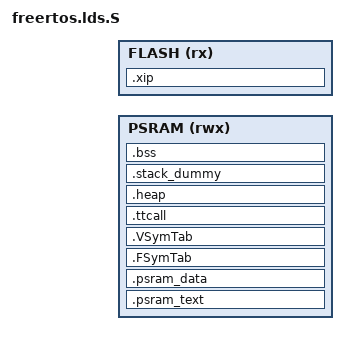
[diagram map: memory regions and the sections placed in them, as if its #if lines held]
/*******************************************************************/
/*                                                                 */
/* This file is automatically generated by linker script generator.*/
/*                                                                 */
/* Version:                                 */
/*                                                                 */
/* Copyright (c) 2010 Xilinx, Inc.  All rights reserved.           */
/*                                                                 */
/* Description : Cortex-A9 Linker Script                          */
/*                                                                 */
/*******************************************************************/
OUTPUT_ARCH("riscv")
OUTPUT_FORMAT("elf64-littleriscv","elf64-littleriscv","elf64-littleriscv")

#if (defined(CONFIG_ROM))
#include "rom_symbol.ld"
#endif

/* Linker script to configure memory regions. */
MEMORY
{
#if (defined(CONFIG_KASAN))
    PSRAM (rwx)   : ORIGIN = CONFIG_ARCH_START_ADDRESS, LENGTH = CONFIG_ARCH_MEM_LENGTH - (CONFIG_ARCH_MEM_LENGTH>>3)
#else
    PSRAM (rwx) : ORIGIN = CONFIG_ARCH_START_ADDRESS, LENGTH = CONFIG_ARCH_MEM_LENGTH
#endif
#if defined(CONFIG_XIP)
#if defined(CONFIG_DRIVERS_SPI_NOR_NG)
	FLASH (rx)  : ORIGIN = CONFIG_XIP_MEM_START_ADDR, LENGTH = CONFIG_XIP_MEM_LEN
#else
	FLASH (rx)  : ORIGIN = 0x10000000, LENGTH = 16M
#endif
#endif
}

__PSRAM_BASE = ORIGIN(PSRAM);
__PSRAM_LENGTH = LENGTH(PSRAM);
__MSP_STACK_LENGTH = 0x100;

__RAM_LENGTH = LENGTH(PSRAM);
#if defined(CONFIG_XIP)
__FLASH_LENGTH = LENGTH(FLASH);
#endif

/* Linker script to place sections and symbol values. Should be used together
 * with other linker script that defines memory regions FLASH and RAM.
 * It references following symbols, which must be defined in code:
 *   Reset_Handler : Entry of reset handler
 *
 * It defines following symbols, which code can use without definition:
 *   __exidx_start
 *   __exidx_end
 *   __etext
 *   __data_start__
 *   __preinit_array_start
 *   __preinit_array_end
 *   __init_array_start
 *   __init_array_end
 *   __fini_array_start
 *   __fini_array_end
 *   __data_end__
 *   __bss_start__
 *   __bss_end__
 *   __end__
 *   end
 *   __HeapLimit
 *   __StackLimit
 *   __StackTop
 *   __stack
 *   _estack
 */
ENTRY(_start)

SECTIONS
{
#if (defined(CONFIG_XIP))
    .xip :
    {
        . = ALIGN(16);
        __xip_start__ = .;
#include "../xip.lds.S"

        *(.xip_text* .xip_rodata*)
        . = ALIGN(16);
        __xip_end__ = .;
    } > FLASH
#endif /* CONFIG_XIP */

    .psram_text :
    {
        . = ALIGN(4);
        __text_start__ = .;
        KEEP(*(.start))
        *(*.text)
        *(.text*)
        *(.nonxip_text*)
        *(.sram_text*)
        KEEP(*(.init))
        KEEP(*(.fini))

#if (defined(CONFIG_KASAN))
        /* .ctors */
        . = ALIGN(8);
        __ctors_start__ = .;
        KEEP(*(.ctors))
        KEEP(*(SORT(.init_array.*)))
        KEEP(*(.init_array))
        __ctors_end__ = .;
#else
        /* .ctors */
        *crtbegin.o(.ctors)
        *crtbegin?.o(.ctors)
        *(EXCLUDE_FILE(*crtend?.o *crtend.o) .ctors)
        *(SORT(.ctors.*))
        *(.ctors)

        /* .dtors */
        *crtbegin.o(.dtors)
        *crtbegin?.o(.dtors)
        *(EXCLUDE_FILE(*crtend?.o *crtend.o) .dtors)
        *(SORT(.dtors.*))
        *(.dtors)
#endif
        *(.rodata*)
        *(.nonxip_rodata*)
        *(.sram_rodata*)

#if (defined(CONFIG_COMPONENTS_CPLUSPLUS_UNWIND))
        __eh_frame_start = .;
        KEEP(*(.eh_frame*))
        __eh_frame_end = .;
        . += 16;
        __gcc_except_table_start = .;
        KEEP(*(.gcc_except_table*))
        __gcc_except_table_end = .;
#endif

        . = ALIGN(4);
        __text_end__ = .;
    } > PSRAM

    . = ALIGN(4);
    __etext = .;
    _sidata = .;

    .psram_data :
    {
        . = ALIGN(4);
        __data_start__ = .;
        _sdata = .;

        *(vtable)
        *(.data*)
        *(.nonxip_data*)
        *(.sram_data*)

        . = ALIGN(4);
        /* preinit data */
        PROVIDE_HIDDEN (__preinit_array_start = .);
        KEEP(*(.preinit_array))
        PROVIDE_HIDDEN (__preinit_array_end = .);

        . = ALIGN(4);
        /* init data */
        PROVIDE_HIDDEN (__init_array_start = .);
        PROVIDE(__ctors_start__ = .);
        KEEP(*(SORT(.init_array.*)))
        KEEP(*(.init_array))
        PROVIDE(__ctors_end__ = .);
        PROVIDE_HIDDEN (__init_array_end = .);

        . = ALIGN(4);
        /* finit data */
        PROVIDE_HIDDEN (__fini_array_start = .);
        KEEP(*(SORT(.fini_array.*)))
        KEEP(*(.fini_array))
        PROVIDE_HIDDEN (__fini_array_end = .);

        KEEP(*(.jcr*))

        . = ALIGN(16);
        __init_process_stack_start__ = .;
        . += 16384;
        __init_process_stack_end__ = .;
        . = ALIGN(CONFIG_HEAP_MIN_ALIGNMENT_SIZE);
        __freertos_irq_stack_bottom = .;
        . += 16384;
        __freertos_irq_stack_top = .;
        PROVIDE( __global_pointer$ = . + 0x400 );

        . = ALIGN(4);
        __data_end__ = .;
        _edata = .;
    } > PSRAM

#if defined(CONFIG_BLEHOST) || defined(CONFIG_USE_SETTINGS_WITHOUT_ZEPHYR)
#if defined(CONFIG_BLEHOST_Z_ITERABLE_SECTION)

/* ROMABLE_REGION_DEFINE_IN_SECTION=0 the common-rom.ld will define as section */
/* ROMABLE_REGION_DEFINE_IN_SECTION=1 the common-rom.ld will define *.o need define in section */
#define ROMABLE_REGION_DEFINE_IN_SECTION 0
/* choose the MEMORY */
#define ZEPHYR_BLE_RAMABLE_REGION     PSRAM
#define ZEPHYR_BLE_ROMABLE_REGION     PSRAM

#include "../../../components/common/thirdparty/bluetooth/zephyr/include/ble/linker/common-ram.ld"
#include "../../../components/common/thirdparty/bluetooth/zephyr/include/ble/linker/common-rom.ld"

#endif /* Z_ITERABLE_SECTION */
#endif /* CONFIG_BLEHOST */

   .FSymTab : {
        _syscall_table_begin = .;
	KEEP(*(FSymTab))
	_syscall_table_end = .;
   } > PSRAM

   .VSymTab : {
        __vsymtab_start = .;
	KEEP(*(VSymTab))
	__vsymtab_end = .;
   } > PSRAM

   .ttcall : {
        _tt_begin = .;
	KEEP(*(ttcall))
	_tt_end = .;
   } > PSRAM

    .heap (COPY):
    {
        __end__ = .;
        __heap_start__ = .;
        _heap_start = .;
        end = __end__;
        *(.heap*)
        __HeapLimit = .;
    } > PSRAM

    /* .stack_dummy section doesn't contains any symbols. It is only
     * used for linker to calculate size of stack sections, and assign
     * values to stack symbols later */
    .stack_dummy (COPY):
    {
        *(.stack*)
    } > PSRAM

    .bss (NOLOAD):
    {
        . = ALIGN(4);
        __bss_start__ = .;
        _sbss = .;

#if CONFIG_COMPONENT_BT || CONFIG_AW_COMPONENT_BLUEDROID_CTRL
        __btc_bss_start__ = .;
        *libxrbtc.a: ( .bss .bss.* .nonxip_bss* .sram_bss* COMMON )
        *libxrbtc.o ( .bss .bss.* .nonxip_bss* .sram_bss* COMMON )
        __btc_bss_end__ = .;
#endif
        *(.bss*)
        *(COMMON)
        *(.nonxip_bss*)
        *(.sram_bss*)

        . = ALIGN(4);
        __bss_end__ = .;
        _ebss = .;
    } > PSRAM

    . = ALIGN(64);

    /* Set stack top to end of RAM, and stack limit move down by
     * size of stack_dummy section */
    __StackTop = ORIGIN(PSRAM) + LENGTH(PSRAM);
    _estack = __StackTop;
    __heap_end__ = _estack - __MSP_STACK_LENGTH;
    _heap_end = __heap_end__;
    __StackLimit = __StackTop - SIZEOF(.stack_dummy);
    PROVIDE(__stack = __StackTop);

    __FLASH_BASE = ORIGIN(FLASH);
    PROVIDE(__XIP_Base = __FLASH_BASE);
#if (defined(CONFIG_XIP))
    PROVIDE(__XIP_End = __xip_end__);
#else
    PROVIDE(__XIP_End = __XIP_Base);
#endif

    /* Check if data + heap + stack exceeds PSRAM limit */
    ASSERT(__StackLimit >= __HeapLimit, "region PSRAM overflowed with stack")
}
